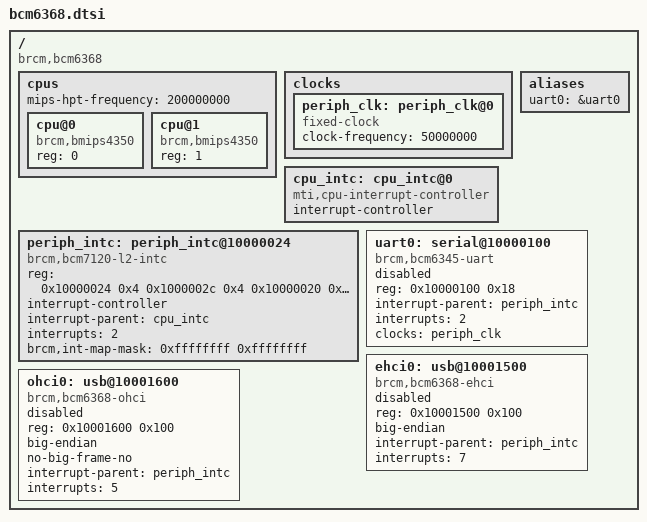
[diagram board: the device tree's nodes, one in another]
/ {
	#address-cells = <1>;
	#size-cells = <1>;
	compatible = "brcm,bcm6368";

	cpus {
		#address-cells = <1>;
		#size-cells = <0>;

		mips-hpt-frequency = <200000000>;

		cpu@0 {
			compatible = "brcm,bmips4350";
			device_type = "cpu";
			reg = <0>;
		};

		cpu@1 {
			compatible = "brcm,bmips4350";
			device_type = "cpu";
			reg = <1>;
		};

	};

	clocks {
		#address-cells = <1>;
		#size-cells = <0>;

		periph_clk: periph_clk@0 {
			compatible = "fixed-clock";
			#clock-cells = <0>;
			clock-frequency = <50000000>;
		};
	};

	aliases {
		uart0 = &uart0;
	};

	cpu_intc: cpu_intc@0 {
		#address-cells = <0>;
		compatible = "mti,cpu-interrupt-controller";

		interrupt-controller;
		#interrupt-cells = <1>;
	};

	periph_intc: periph_intc@10000024 {
		compatible = "brcm,bcm7120-l2-intc";
		reg = <0x10000024 0x4 0x1000002c 0x4
		       0x10000020 0x4 0x10000028 0x4>;

		interrupt-controller;
		#interrupt-cells = <1>;

		interrupt-parent = <&cpu_intc>;
		interrupts = <2>;
		brcm,int-map-mask = <0xffffffff 0xffffffff>;
	};

	uart0: serial@10000100 {
		compatible = "brcm,bcm6345-uart";
		reg = <0x10000100 0x18>;
		interrupt-parent = <&periph_intc>;
		interrupts = <2>;
		clocks = <&periph_clk>;
		status = "disabled";
	};

	ehci0: usb@10001500 {
		compatible = "brcm,bcm6368-ehci", "generic-ehci";
		reg = <0x10001500 0x100>;
		big-endian;
		interrupt-parent = <&periph_intc>;
		interrupts = <7>;
		status = "disabled";
	};

	ohci0: usb@10001600 {
		compatible = "brcm,bcm6368-ohci", "generic-ohci";
		reg = <0x10001600 0x100>;
		big-endian;
		no-big-frame-no;
		interrupt-parent = <&periph_intc>;
		interrupts = <5>;
		status = "disabled";
	};
};
